AUTOSAR XML (schema 00046)
package /ComponentTypes
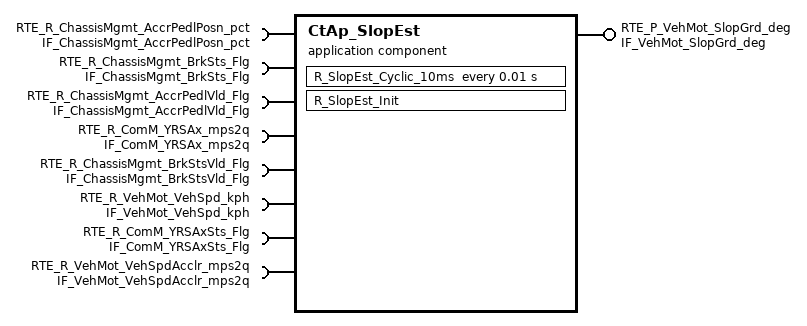
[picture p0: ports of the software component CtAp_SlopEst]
  application sw component type CtAp_SlopEst
    provide port RTE_P_VehMot_SlopGrd_deg: nonqueued-sender-com-spec{data-element=tec_VehMot_SlopGrd_deg, init-value=0}, provided-interface=IF_VehMot_SlopGrd_deg
    8 x require port:
      RTE_R_ChassisMgmt_AccrPedlPosn_pct: nonqueued-receiver-com-spec{data-element=tec_ChassisMgmt_AccrPedlPosn_pct, filter=data-filter-type=ALWAYS, init-value=0}, required-interface=IF_ChassisMgmt_AccrPedlPosn_pct
      RTE_R_ChassisMgmt_BrkSts_Flg: nonqueued-receiver-com-spec{data-element=tec_ChassisMgmt_BrkSts_Flg, filter=data-filter-type=ALWAYS, init-value=0}, required-interface=IF_ChassisMgmt_BrkSts_Flg
      RTE_R_ChassisMgmt_AccrPedlVld_Flg: nonqueued-receiver-com-spec{data-element=tec_ChassisMgmt_AccrPedlVld_Flg, filter=data-filter-type=ALWAYS, init-value=0}, required-interface=IF_ChassisMgmt_AccrPedlVld_Flg
      RTE_R_ComM_YRSAx_mps2q: nonqueued-receiver-com-spec{data-element=tec_ComM_YRSAx_mps2q, filter=data-filter-type=ALWAYS, init-value=0}, required-interface=IF_ComM_YRSAx_mps2q
      RTE_R_ChassisMgmt_BrkStsVld_Flg: nonqueued-receiver-com-spec{data-element=tec_ChassisMgmt_BrkStsVld_Flg, filter=data-filter-type=ALWAYS, init-value=0}, required-interface=IF_ChassisMgmt_BrkStsVld_Flg
      RTE_R_VehMot_VehSpd_kph: nonqueued-receiver-com-spec{data-element=tec_VehMot_VehSpd_kph, filter=data-filter-type=ALWAYS, init-value=0}, required-interface=IF_VehMot_VehSpd_kph
      RTE_R_ComM_YRSAxSts_Flg: nonqueued-receiver-com-spec{data-element=tec_ComM_YRSAxSts_Flg, filter=data-filter-type=ALWAYS, init-value=0}, required-interface=IF_ComM_YRSAxSts_Flg
      RTE_R_VehMot_VehSpdAcclr_mps2q: nonqueued-receiver-com-spec{data-element=tec_VehMot_VehSpdAcclr_mps2q, filter=data-filter-type=ALWAYS, init-value=0}, required-interface=IF_VehMot_VehSpdAcclr_mps2q
    behavior CtAp_SlopEst_InternalBehavior
      init event CtAp_SlopEst_InitEvent: start-on-event=R_SlopEst_Init
      timing event TMT_R_SlopEst_Cyclic_10ms: start-on-event=R_SlopEst_Cyclic_10ms, period=0.01
      runnable R_SlopEst_Init
      runnable R_SlopEst_Cyclic_10ms
        data-receive-point-by-arguments:
          8 x access:
            REC_RTE_R_ChassisMgmt_AccrPedlPosn_pct_tec_ChassisMgmt_AccrPedlPosn_pct: accessed-variable=RTE_R_ChassisMgmt_AccrPedlPosn_pct.tec_ChassisMgmt_AccrPedlPosn_pct
            REC_RTE_R_ChassisMgmt_AccrPedlVld_Flg_tec_ChassisMgmt_AccrPedlVld_Flg: accessed-variable=RTE_R_ChassisMgmt_AccrPedlVld_Flg.tec_ChassisMgmt_AccrPedlVld_Flg
            REC_RTE_R_ChassisMgmt_BrkStsVld_Flg_tec_ChassisMgmt_BrkStsVld_Flg: accessed-variable=RTE_R_ChassisMgmt_BrkStsVld_Flg.tec_ChassisMgmt_BrkStsVld_Flg
            REC_RTE_R_ChassisMgmt_BrkSts_Flg_tec_ChassisMgmt_BrkSts_Flg: accessed-variable=RTE_R_ChassisMgmt_BrkSts_Flg.tec_ChassisMgmt_BrkSts_Flg
            REC_RTE_R_ComM_YRSAxSts_Flg_tec_ComM_YRSAxSts_Flg: accessed-variable=RTE_R_ComM_YRSAxSts_Flg.tec_ComM_YRSAxSts_Flg
            REC_RTE_R_ComM_YRSAx_mps2q_tec_ComM_YRSAx_mps2q: accessed-variable=RTE_R_ComM_YRSAx_mps2q.tec_ComM_YRSAx_mps2q
            REC_RTE_R_VehMot_VehSpdAcclr_mps2q_tec_VehMot_VehSpdAcclr_mps2q: accessed-variable=RTE_R_VehMot_VehSpdAcclr_mps2q.tec_VehMot_VehSpdAcclr_mps2q
            REC_RTE_R_VehMot_VehSpd_kph_tec_VehMot_VehSpd_kph: accessed-variable=RTE_R_VehMot_VehSpd_kph.tec_VehMot_VehSpd_kph
        data-send-points:
          access SEND_RTE_P_VehMot_SlopGrd_deg_tec_VehMot_SlopGrd_deg: accessed-variable=RTE_P_VehMot_SlopGrd_deg.tec_VehMot_SlopGrd_deg
  swc implementation CtAp_SlopEst_Implementation: behavior=CtAp_SlopEst_InternalBehavior
    code-descriptors:
      code Default: artifact-descriptors=autosar-engineering-object=category=SWOBJ
